AUTOSAR XML (schema 4-0-3)
package /AUTOSAR_BswM  # Basic Software Mode Manager
package /AUTOSAR_BswM/units
  unit DummyUnit
package /AUTOSAR_BswM/SwComponentTypes_OsApplication_C0
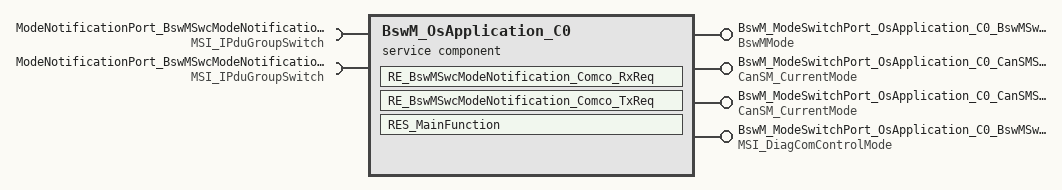
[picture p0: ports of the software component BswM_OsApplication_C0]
  service sw component type BswM_OsApplication_C0
    4 x provide port:
      BswM_ModeSwitchPort_OsApplication_C0_BswMSwitchPort_Rte: mode-switch-sender-com-spec{mode-group=CurrentMode, queue-length=3}, provided-interface=BswMMode
      BswM_ModeSwitchPort_OsApplication_C0_CanSMState_PublicCan: provided-interface=CanSM_CurrentMode
      BswM_ModeSwitchPort_OsApplication_C0_CanSMState_PrivateCan: provided-interface=CanSM_CurrentMode
      BswM_ModeSwitchPort_OsApplication_C0_BswMSwitchPort_DiagComControlState: provided-interface=MSI_DiagComControlMode
    require port ModeNotificationPort_BswMSwcModeNotification_Comco_RxReq: mode-switch-receiver-com-spec{enhanced-mode-api=1, supports-asynchronous-mode-switch=0}, required-interface=MSI_IPduGroupSwitch
    require port ModeNotificationPort_BswMSwcModeNotification_Comco_TxReq: mode-switch-receiver-com-spec{enhanced-mode-api=1, supports-asynchronous-mode-switch=0}, required-interface=MSI_IPduGroupSwitch
    behavior BswMInternalBehavior: data-type-mapping=[DataTypeMappingSet_0, ModeMapping, BswMModeMapping, BswMModeMapping_CrossCore, DataTypeMappingSet_CanSM], handle-termination-and-restart=CAN-BE-TERMINATED-AND-RESTARTED
      4 x swc mode switch event, all with activation=ON-ENTRY:
        MSE_BswMSwcModeNotification_Comco_RxReq_PDU_GROUP_START: start-on-event=RE_BswMSwcModeNotification_Comco_RxReq, mode=ModeNotificationPort_BswMSwcModeNotification_Comco_RxReq.proto_MDG_IPduGroupSwitch.PDU_GROUP_START
        MSE_BswMSwcModeNotification_Comco_RxReq_PDU_GROUP_STOP: start-on-event=RE_BswMSwcModeNotification_Comco_RxReq, mode=ModeNotificationPort_BswMSwcModeNotification_Comco_RxReq.proto_MDG_IPduGroupSwitch.PDU_GROUP_STOP
        MSE_BswMSwcModeNotification_Comco_TxReq_PDU_GROUP_START: start-on-event=RE_BswMSwcModeNotification_Comco_TxReq, mode=ModeNotificationPort_BswMSwcModeNotification_Comco_TxReq.proto_MDG_IPduGroupSwitch.PDU_GROUP_START
        MSE_BswMSwcModeNotification_Comco_TxReq_PDU_GROUP_STOP: start-on-event=RE_BswMSwcModeNotification_Comco_TxReq, mode=ModeNotificationPort_BswMSwcModeNotification_Comco_TxReq.proto_MDG_IPduGroupSwitch.PDU_GROUP_STOP
      included-mode-declaration-group-sets:
        mode-declaration-group=DcmEcuReset, prefix=BSWM_
        mode-declaration-group=MDG_IPduGroupSwitch, prefix=BSWM_
        mode-declaration-group=DcmCommunicationControl, prefix=BSWM_
        mode-declaration-group=BswMModeGroup, prefix=BSWM_
        mode-declaration-group=CANSM_ModeGroup, prefix=BSWM_
      runnable RE_BswMSwcModeNotification_Comco_RxReq: mode-access-point=ModeNotificationPort_BswMSwcModeNotification_Comco_RxReq.proto_MDG_IPduGroupSwitch, symbol=BswM_1_OsApplication_C0_MRPFunc_BswMSwcModeNotification_Comco_RxReq
      runnable RE_BswMSwcModeNotification_Comco_TxReq: mode-access-point=ModeNotificationPort_BswMSwcModeNotification_Comco_TxReq.proto_MDG_IPduGroupSwitch, symbol=BswM_1_OsApplication_C0_MRPFunc_BswMSwcModeNotification_Comco_TxReq
      runnable RES_MainFunction: symbol=BswM_1_OsApplication_C0_MainFunction
        4 x mode switch point:
          RES_MainFunction_to_BswMSwitchPort_Rte: mode-group=BswM_ModeSwitchPort_OsApplication_C0_BswMSwitchPort_Rte.CurrentMode
          RES_MainFunction_to_CanSMState_PublicCan: mode-group=BswM_ModeSwitchPort_OsApplication_C0_CanSMState_PublicCan.proto_CANSM_ModeGroup
          RES_MainFunction_to_CanSMState_PrivateCan: mode-group=BswM_ModeSwitchPort_OsApplication_C0_CanSMState_PrivateCan.proto_CANSM_ModeGroup
          RES_MainFunction_to_BswMSwitchPort_DiagComControlState: mode-group=BswM_ModeSwitchPort_OsApplication_C0_BswMSwitchPort_DiagComControlState.proto_DcmCommunicationControl
package /AUTOSAR_BswM/SwComponentTypes_OsApplication_C1
  service sw component type BswM_OsApplication_C1
    behavior BswMInternalBehavior: data-type-mapping=[DataTypeMappingSet_0, ModeMapping, BswMModeMapping, BswMModeMapping_CrossCore], handle-termination-and-restart=CAN-BE-TERMINATED-AND-RESTARTED, included-mode-declaration-group-set{mode-declaration-group=BSWM_ModeGroupCrossCore, prefix=BSWM_}
      runnable RES_MainFunction: symbol=BswM_1_OsApplication_C1_MainFunction
package /AUTOSAR_BswM/SwComponentTypes_OsApplication_C2
  service sw component type BswM_OsApplication_C2
    behavior BswMInternalBehavior: data-type-mapping=[DataTypeMappingSet_0, ModeMapping, BswMModeMapping, BswMModeMapping_CrossCore], handle-termination-and-restart=CAN-BE-TERMINATED-AND-RESTARTED, included-mode-declaration-group-set{mode-declaration-group=BSWM_ModeGroupCrossCore, prefix=BSWM_}
      runnable RES_MainFunction: symbol=BswM_1_OsApplication_C2_MainFunction
package /AUTOSAR_BswM/SwComponentTypes_OsApplication_C3
  service sw component type BswM_OsApplication_C3
    behavior BswMInternalBehavior: data-type-mapping=[DataTypeMappingSet_0, ModeMapping, BswMModeMapping, BswMModeMapping_CrossCore], handle-termination-and-restart=CAN-BE-TERMINATED-AND-RESTARTED, included-mode-declaration-group-set{mode-declaration-group=BSWM_ModeGroupCrossCore, prefix=BSWM_}
      runnable RES_MainFunction: symbol=BswM_1_OsApplication_C3_MainFunction
package /AUTOSAR_BswM/SwcImplementations
  4 x swc implementation, all with programming-language=C, sw-version=1.1.1, vendor-id=1:
    BswMImplementation_OsApplication_C0: behavior=BswM_OsApplication_C0/BswMInternalBehavior
      code-descriptors:
        code BswMImplementationEB: artifact-descriptors=autosar-engineering-object={short-label=BswMEngObject, category=SWSRC}
      resource consumption Resources
        memory section CODE: sw-addrmethod=CODE
    BswMImplementation_OsApplication_C1: behavior=BswM_OsApplication_C1/BswMInternalBehavior
      code-descriptors:
        code BswMImplementationEB: artifact-descriptors=autosar-engineering-object={short-label=BswMEngObject, category=SWSRC}
      resource consumption Resources
        memory section CODE: sw-addrmethod=CODE
    BswMImplementation_OsApplication_C2: behavior=BswM_OsApplication_C2/BswMInternalBehavior
      code-descriptors:
        code BswMImplementationEB: artifact-descriptors=autosar-engineering-object={short-label=BswMEngObject, category=SWSRC}
      resource consumption Resources
        memory section CODE: sw-addrmethod=CODE
    BswMImplementation_OsApplication_C3: behavior=BswM_OsApplication_C3/BswMInternalBehavior
      code-descriptors:
        code BswMImplementationEB: artifact-descriptors=autosar-engineering-object={short-label=BswMEngObject, category=SWSRC}
      resource consumption Resources
        memory section CODE: sw-addrmethod=CODE
